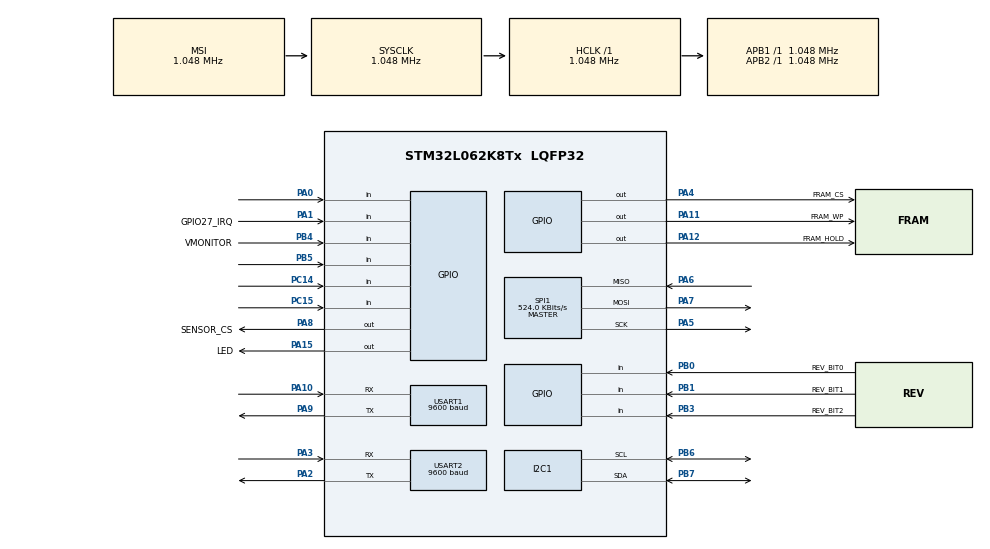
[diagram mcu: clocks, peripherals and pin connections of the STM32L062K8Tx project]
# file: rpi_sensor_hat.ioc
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I2C1.OwnAddress=1
I2C1.Timing=0x00000202
Mcu.Family=STM32L0
Mcu.Name=STM32L062K8Tx
Mcu.Package=LQFP32
PA0.GPIO_PuPd=GPIO_PULLDOWN
PA0.Signal=GPIO_Input
PA1.GPIO_Label=GPIO27_IRQ
PA1.GPIO_PuPd=GPIO_PULLDOWN
PA1.Signal=GPIO_Input
PA10.Mode=Asynchronous
PA10.Signal=USART1_RX
PA11.GPIO_Label=FRAM_WP
PA11.PinState=GPIO_PIN_SET
PA11.Signal=GPIO_Output
PA12.GPIO_Label=FRAM_HOLD
PA12.PinState=GPIO_PIN_SET
PA12.Signal=GPIO_Output
PA13.Mode=Serial_Wire
PA13.Signal=SYS_SWDIO
PA14.Mode=Serial_Wire
PA14.Signal=SYS_SWCLK
PA15.GPIO_Label=LED
PA15.Signal=GPIO_Output
PA2.Mode=Asynchronous
PA2.Signal=USART2_TX
PA3.Mode=Asynchronous
PA3.Signal=USART2_RX
PA4.GPIO_Label=FRAM_CS
PA4.PinState=GPIO_PIN_SET
PA4.Signal=GPIO_Output
PA5.Mode=Full_Duplex_Master
PA5.Signal=SPI1_SCK
PA6.Mode=Full_Duplex_Master
PA6.Signal=SPI1_MISO
PA7.Mode=Full_Duplex_Master
PA7.Signal=SPI1_MOSI
PA8.GPIO_Label=SENSOR_CS
PA8.PinState=GPIO_PIN_SET
PA8.Signal=GPIO_Output
PA9.Mode=Asynchronous
PA9.Signal=USART1_TX
PB0.GPIO_Label=REV_BIT0
PB0.Signal=GPIO_Input
PB1.GPIO_Label=REV_BIT1
PB1.Signal=GPIO_Input
PB3.GPIO_Label=REV_BIT2
PB3.Signal=GPIO_Input
PB4.GPIO_Label=VMONITOR
PB4.Signal=GPIO_Input
PB5.GPIO_PuPd=GPIO_PULLDOWN
PB5.Signal=GPIO_Input
PB6.Mode=I2C
PB6.Signal=I2C1_SCL
PB7.Mode=I2C
PB7.Signal=I2C1_SDA
PC14-OSC32_IN.GPIO_PuPd=GPIO_PULLDOWN
PC14-OSC32_IN.Signal=GPIO_Input
PC15-OSC32_OUT.GPIO_PuPd=GPIO_PULLDOWN
PC15-OSC32_OUT.Signal=GPIO_Input
ProjectManager.HeapSize=0x200
ProjectManager.StackSize=0x400
ProjectManager.TargetToolchain=STM32CubeIDE
RCC.AHBFreq_Value=1048000
RCC.APB1Freq_Value=1048000
RCC.APB1TimFreq_Value=1048000
RCC.APB2Freq_Value=1048000
RCC.APB2TimFreq_Value=1048000
RCC.HCLKFreq_Value=1048000
RCC.HSI16_VALUE=16000000
RCC.HSI48_VALUE=48000000
RCC.HSI_VALUE=16000000
RCC.LSE_VALUE=32768
RCC.MSIClockRange=RCC_MSIRANGE_4
RCC.MSI_VALUE=1048000
RCC.SYSCLKFreq_VALUE=1048000
RCC.VCOOutputFreq_Value=48000000
SPI1.CalculateBaudRate=524.0 KBits/s
SPI1.Direction=SPI_DIRECTION_2LINES
SPI1.Mode=SPI_MODE_MASTER
SPI1.VirtualType=VM_MASTER
USART1.BaudRate=9600
USART1.VirtualMode-Asynchronous=VM_ASYNC
USART2.BaudRate=9600
USART2.VirtualMode-Asynchronous=VM_ASYNC
board=custom

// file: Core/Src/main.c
/* USER CODE BEGIN Header */
/**
  ******************************************************************************
  * @file           : main.c
  * @brief          : Main program body
  ******************************************************************************
  * @attention
  *
  * <h2><center>&copy; Copyright (c) 2021 STMicroelectronics.
  * All rights reserved.</center></h2>
  *
  * This software component is licensed by ST under BSD 3-Clause license,
  * the "License"; You may not use this file except in compliance with the
  * License. You may obtain a copy of the License at:
  *                        opensource.org/licenses/BSD-3-Clause
  *
  ******************************************************************************
  */
/* USER CODE END Header */
#include "main.h"

/* USER CODE BEGIN Includes */
#include <stdio.h>
#include <errno.h>
#include <sys/unistd.h>

/* USER CODE END Includes */

I2C_HandleTypeDef hi2c1;

SPI_HandleTypeDef hspi1;

UART_HandleTypeDef huart1;
UART_HandleTypeDef huart2;

void SystemClock_Config(void);
static void MX_GPIO_Init(void);
static void MX_I2C1_Init(void);
static void MX_SPI1_Init(void);
static void MX_USART1_UART_Init(void);
static void MX_USART2_UART_Init(void);

int main(void)
{

  /* MCU Configuration--------------------------------------------------------*/

  /* Reset of all peripherals, Initializes the Flash interface and the Systick. */
  HAL_Init();

  /* Configure the system clock */
  SystemClock_Config();

  /* Initialize all configured peripherals */
  MX_GPIO_Init();
  MX_I2C1_Init();
  MX_SPI1_Init();
  MX_USART1_UART_Init();
  MX_USART2_UART_Init();

  /* Infinite loop */
  while (1)
  {
	  HAL_GPIO_WritePin(LED_GPIO_Port, LED_Pin, GPIO_PIN_RESET);
	  printf("LED is off\n");
	  HAL_Delay(1000);
	  HAL_GPIO_WritePin(LED_GPIO_Port, LED_Pin, GPIO_PIN_SET);
	  printf("LED is on\n");
	  HAL_Delay(1000);

  }
}

void SystemClock_Config(void)
{
  RCC_OscInitTypeDef RCC_OscInitStruct = {0};
  RCC_ClkInitTypeDef RCC_ClkInitStruct = {0};
  RCC_PeriphCLKInitTypeDef PeriphClkInit = {0};

  /** Configure the main internal regulator output voltage
  */
  __HAL_PWR_VOLTAGESCALING_CONFIG(PWR_REGULATOR_VOLTAGE_SCALE1);
  /** Initializes the RCC Oscillators according to the specified parameters
  * in the RCC_OscInitTypeDef structure.
  */
  RCC_OscInitStruct.OscillatorType = RCC_OSCILLATORTYPE_MSI;
  RCC_OscInitStruct.MSIState = RCC_MSI_ON;
  RCC_OscInitStruct.MSICalibrationValue = 0;
  RCC_OscInitStruct.MSIClockRange = RCC_MSIRANGE_4;
  RCC_OscInitStruct.PLL.PLLState = RCC_PLL_NONE;
  if (HAL_RCC_OscConfig(&RCC_OscInitStruct) != HAL_OK)
  {
    Error_Handler();
  }
  /** Initializes the CPU, AHB and APB buses clocks
  */
  RCC_ClkInitStruct.ClockType = RCC_CLOCKTYPE_HCLK|RCC_CLOCKTYPE_SYSCLK
                              |RCC_CLOCKTYPE_PCLK1|RCC_CLOCKTYPE_PCLK2;
  RCC_ClkInitStruct.SYSCLKSource = RCC_SYSCLKSOURCE_MSI;
  RCC_ClkInitStruct.AHBCLKDivider = RCC_SYSCLK_DIV1;
  RCC_ClkInitStruct.APB1CLKDivider = RCC_HCLK_DIV1;
  RCC_ClkInitStruct.APB2CLKDivider = RCC_HCLK_DIV1;

  if (HAL_RCC_ClockConfig(&RCC_ClkInitStruct, FLASH_LATENCY_0) != HAL_OK)
  {
    Error_Handler();
  }
  PeriphClkInit.PeriphClockSelection = RCC_PERIPHCLK_USART1|RCC_PERIPHCLK_USART2
                              |RCC_PERIPHCLK_I2C1;
  PeriphClkInit.Usart1ClockSelection = RCC_USART1CLKSOURCE_PCLK2;
  PeriphClkInit.Usart2ClockSelection = RCC_USART2CLKSOURCE_PCLK1;
  PeriphClkInit.I2c1ClockSelection = RCC_I2C1CLKSOURCE_PCLK1;
  if (HAL_RCCEx_PeriphCLKConfig(&PeriphClkInit) != HAL_OK)
  {
    Error_Handler();
  }
}

static void MX_I2C1_Init(void)
{

  hi2c1.Instance = I2C1;
  hi2c1.Init.Timing = 0x00000202;
  hi2c1.Init.OwnAddress1 = 2;
  hi2c1.Init.AddressingMode = I2C_ADDRESSINGMODE_7BIT;
  hi2c1.Init.DualAddressMode = I2C_DUALADDRESS_DISABLE;
  hi2c1.Init.OwnAddress2 = 0;
  hi2c1.Init.OwnAddress2Masks = I2C_OA2_NOMASK;
  hi2c1.Init.GeneralCallMode = I2C_GENERALCALL_DISABLE;
  hi2c1.Init.NoStretchMode = I2C_NOSTRETCH_DISABLE;
  if (HAL_I2C_Init(&hi2c1) != HAL_OK)
  {
    Error_Handler();
  }
  /** Configure Analogue filter
  */
  if (HAL_I2CEx_ConfigAnalogFilter(&hi2c1, I2C_ANALOGFILTER_ENABLE) != HAL_OK)
  {
    Error_Handler();
  }
  /** Configure Digital filter
  */
  if (HAL_I2CEx_ConfigDigitalFilter(&hi2c1, 0) != HAL_OK)
  {
    Error_Handler();
  }

}

static void MX_SPI1_Init(void)
{

  /* SPI1 parameter configuration*/
  hspi1.Instance = SPI1;
  hspi1.Init.Mode = SPI_MODE_MASTER;
  hspi1.Init.Direction = SPI_DIRECTION_2LINES;
  hspi1.Init.DataSize = SPI_DATASIZE_8BIT;
  hspi1.Init.CLKPolarity = SPI_POLARITY_LOW;
  hspi1.Init.CLKPhase = SPI_PHASE_1EDGE;
  hspi1.Init.NSS = SPI_NSS_SOFT;
  hspi1.Init.BaudRatePrescaler = SPI_BAUDRATEPRESCALER_2;
  hspi1.Init.FirstBit = SPI_FIRSTBIT_MSB;
  hspi1.Init.TIMode = SPI_TIMODE_DISABLE;
  hspi1.Init.CRCCalculation = SPI_CRCCALCULATION_DISABLE;
  hspi1.Init.CRCPolynomial = 7;
  if (HAL_SPI_Init(&hspi1) != HAL_OK)
  {
    Error_Handler();
  }

}

static void MX_USART1_UART_Init(void)
{

  huart1.Instance = USART1;
  huart1.Init.BaudRate = 9600;
  huart1.Init.WordLength = UART_WORDLENGTH_8B;
  huart1.Init.StopBits = UART_STOPBITS_1;
  huart1.Init.Parity = UART_PARITY_NONE;
  huart1.Init.Mode = UART_MODE_TX_RX;
  huart1.Init.HwFlowCtl = UART_HWCONTROL_NONE;
  huart1.Init.OverSampling = UART_OVERSAMPLING_16;
  huart1.Init.OneBitSampling = UART_ONE_BIT_SAMPLE_DISABLE;
  huart1.AdvancedInit.AdvFeatureInit = UART_ADVFEATURE_NO_INIT;
  if (HAL_UART_Init(&huart1) != HAL_OK)
  {
    Error_Handler();
  }

}

static void MX_USART2_UART_Init(void)
{

  huart2.Instance = USART2;
  huart2.Init.BaudRate = 9600;
  huart2.Init.WordLength = UART_WORDLENGTH_8B;
  huart2.Init.StopBits = UART_STOPBITS_1;
  huart2.Init.Parity = UART_PARITY_NONE;
  huart2.Init.Mode = UART_MODE_TX_RX;
  huart2.Init.HwFlowCtl = UART_HWCONTROL_NONE;
  huart2.Init.OverSampling = UART_OVERSAMPLING_16;
  huart2.Init.OneBitSampling = UART_ONE_BIT_SAMPLE_DISABLE;
  huart2.AdvancedInit.AdvFeatureInit = UART_ADVFEATURE_NO_INIT;
  if (HAL_UART_Init(&huart2) != HAL_OK)
  {
    Error_Handler();
  }

}

static void MX_GPIO_Init(void)
{
  GPIO_InitTypeDef GPIO_InitStruct = {0};

  /* GPIO Ports Clock Enable */
  __HAL_RCC_GPIOC_CLK_ENABLE();
  __HAL_RCC_GPIOA_CLK_ENABLE();
  __HAL_RCC_GPIOB_CLK_ENABLE();

  /*Configure GPIO pin Output Level */
  HAL_GPIO_WritePin(GPIOA, FRAM_CS_Pin|SENSOR_CS_Pin|FRAM_WP_Pin|FRAM_HOLD_Pin, GPIO_PIN_SET);

  /*Configure GPIO pin Output Level */
  HAL_GPIO_WritePin(LED_GPIO_Port, LED_Pin, GPIO_PIN_RESET);

  /*Configure GPIO pins : PC14 PC15 */
  GPIO_InitStruct.Pin = GPIO_PIN_14|GPIO_PIN_15;
  GPIO_InitStruct.Mode = GPIO_MODE_INPUT;
  GPIO_InitStruct.Pull = GPIO_PULLDOWN;
  HAL_GPIO_Init(GPIOC, &GPIO_InitStruct);

  /*Configure GPIO pins : PA0 GPIO27_IRQ_Pin */
  GPIO_InitStruct.Pin = GPIO_PIN_0|GPIO27_IRQ_Pin;
  GPIO_InitStruct.Mode = GPIO_MODE_INPUT;
  GPIO_InitStruct.Pull = GPIO_PULLDOWN;
  HAL_GPIO_Init(GPIOA, &GPIO_InitStruct);

  /*Configure GPIO pins : FRAM_CS_Pin SENSOR_CS_Pin FRAM_WP_Pin FRAM_HOLD_Pin
                           LED_Pin */
  GPIO_InitStruct.Pin = FRAM_CS_Pin|SENSOR_CS_Pin|FRAM_WP_Pin|FRAM_HOLD_Pin
                          |LED_Pin;
  GPIO_InitStruct.Mode = GPIO_MODE_OUTPUT_PP;
  GPIO_InitStruct.Pull = GPIO_NOPULL;
  GPIO_InitStruct.Speed = GPIO_SPEED_FREQ_LOW;
  HAL_GPIO_Init(GPIOA, &GPIO_InitStruct);

  /*Configure GPIO pins : REV_BIT0_Pin REV_BIT1_Pin REV_BIT2_Pin VMONITOR_Pin */
  GPIO_InitStruct.Pin = REV_BIT0_Pin|REV_BIT1_Pin|REV_BIT2_Pin|VMONITOR_Pin;
  GPIO_InitStruct.Mode = GPIO_MODE_INPUT;
  GPIO_InitStruct.Pull = GPIO_NOPULL;
  HAL_GPIO_Init(GPIOB, &GPIO_InitStruct);

  /*Configure GPIO pin : PB5 */
  GPIO_InitStruct.Pin = GPIO_PIN_5;
  GPIO_InitStruct.Mode = GPIO_MODE_INPUT;
  GPIO_InitStruct.Pull = GPIO_PULLDOWN;
  HAL_GPIO_Init(GPIOB, &GPIO_InitStruct);

}

/* USER CODE BEGIN 4 */
int _write(int file, char *data, int len)
{
	if((file != STDOUT_FILENO) && (file != STDERR_FILENO))
	{
		errno = EBADF;
		return -1;
	}
	HAL_StatusTypeDef status = HAL_UART_Transmit(&huart2, (uint8_t *)data, len, 1000);
	return (status == HAL_OK ? len : 0);
}

/* USER CODE END 4 */

void Error_Handler(void)
{
  __disable_irq();
  while (1)
  {
  }
}

/************************ (C) COPYRIGHT STMicroelectronics *****END OF FILE****/
